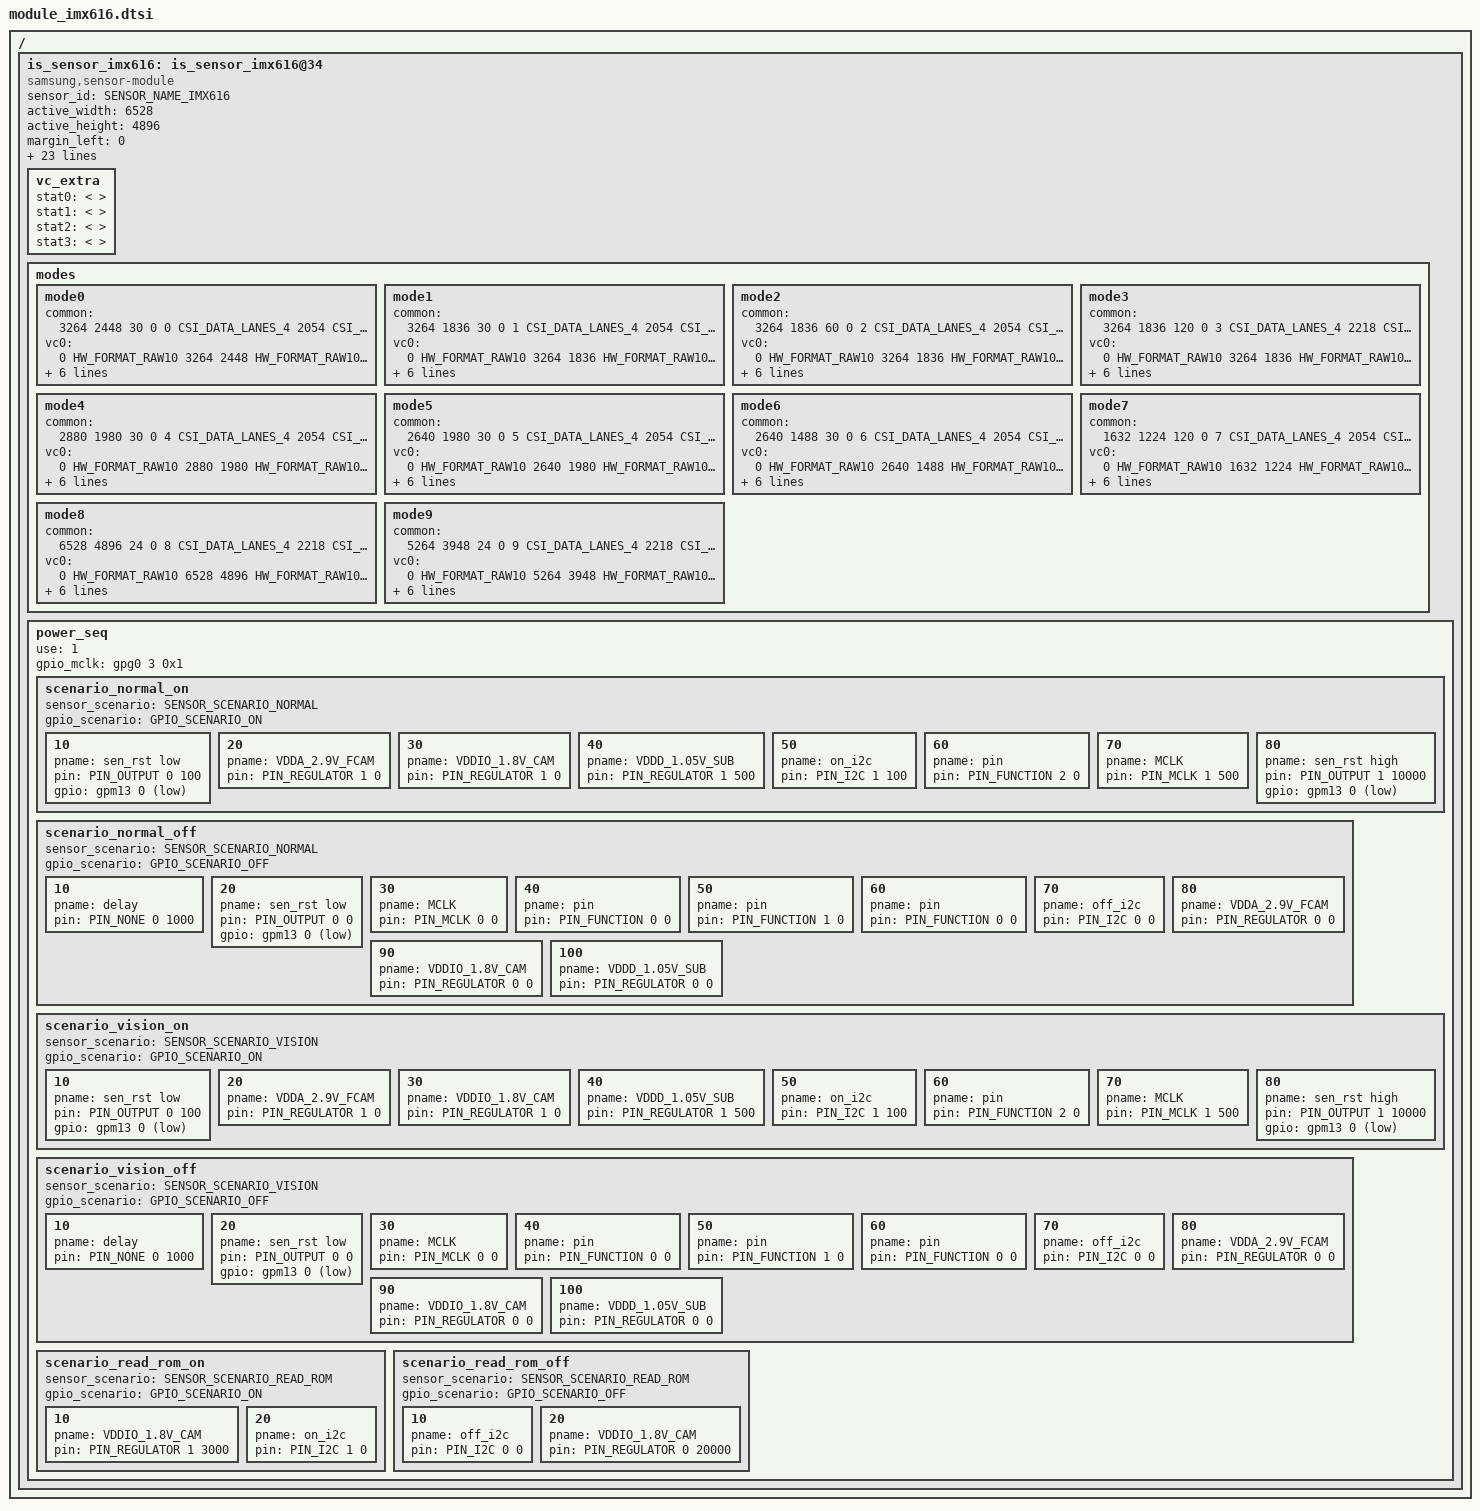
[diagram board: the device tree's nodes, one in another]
/*
 * SAMSUNG EXYNOSxxxx board camera device tree source
 *
 * Copyright (c) 2021 Samsung Electronics Co., Ltd.
 *		http://www.samsung.com
 *
 * This program is free software; you can redistribute it and/or modify
 * it under the terms of the GNU General Public License version 2 as
 * published by the Free Software Foundation.
 */

#include <dt-bindings/camera/exynos_is_dt.h>

#ifndef USE_VENDOR_PWR_PIN_NAME
#define IMX616_IOVDD	<>     /* CAM_VDDIO_1P8 : CAM0_VLDO3 is used for all camera commonly */
#define IMX616_AVDD	<>     /* RCAM1_AVDD1_2P9 */
#define IMX616_DVDD	<>     /* RCAM1_DVDD_1P1 */
#endif

/ {
	fragment@camera {
		target-path = "/";
		__overlay__ {
			is_sensor_imx616: is_sensor_imx616@34 {
				compatible = "samsung,sensor-module";

				/* common */
				sensor_id = <SENSOR_NAME_IMX616>;
				active_width = <6528>;
				active_height = <4896>;
				margin_left = <0>;
				margin_right = <0>;
				margin_top = <0>;
				margin_bottom = <0>;
				max_framerate = <120>;
				bitwidth = <10>;
				use_retention_mode = <SENSOR_RETENTION_INACTIVE>;
				sensor_maker = "SONY";
				sensor_name = "IMX616";
				setfile_name = "setfile_imx616.bin";

				imx616_iovdd-supply = IMX616_IOVDD;
				imx616_avdd-supply = IMX616_AVDD;
				imx616_dvdd-supply = IMX616_DVDD;

				status = "okay";

				/* board */
				pinctrl-names = "pin0", "pin1", "pin2", "release";
				pinctrl-0 = <>;
				pinctrl-1 = <&sensor_mclk1_out>;
				pinctrl-2 = <&sensor_mclk1_fn>;
				pinctrl-3 = <>;

				position = <1>;	/* Rear:0. Front:1. Rear_sub:2. Secure:3. */
				id = <1>; /* is_sensor id */
				mclk_ch = <1>;
				sensor_i2c_ch = <5>; /* SENSOR_CONTROL_I2C4 */

				/* vendor */
				rom_type = <2>; /* ROM_TYPE_EEPROM */
				rom_id = <1>;
				rom_cal_index = <0>;

				vc_extra {
					/* ex) statX = <stat_type, sensor_mode, max_width, max_height, max_element> */
					/* VC_BUF_DATA_TYPE_SENSOR_STAT1 */
					stat0 = </* not available */>;
					/* VC_BUF_DATA_TYPE_GENERAL_STAT1 */
					stat1 = </* not available */>;
					/* VC_BUF_DATA_TYPE_SENSOR_STAT2 */
					stat2 = </* not available */>;
					/* VC_BUF_DATA_TYPE_GENERAL_STAT2 */
					stat3 = </* not available */>;
				};

				/*
				 * Reference File : IMX616-AAJH5_SAM-DPHY_26MHz_RegisterSetting_ver14.00-20.01_b1_191023.xlsx
				 *
				 * -. 2x2 BIN For Single Still Preview / Capture / Video -
				 *    [ 0 ] REG_H : 2x2 Binning 3264x2448 30fps    : Single Still Preview (4:3)     ,  MIPI lane: 4, MIPI data rate(Mbps/lane): 2054
				 *    [ 1 ] REG_I : 2x2 Binning 3264x1836 30fps    : Single Still Preview (16:9)    ,  MIPI lane: 4, MIPI data rate(Mbps/lane): 2054
				 *    [ 2 ] REG_T : 2x2 Binning 3264x1836 60fps    : Single Video (16:9)            ,  MIPI lane: 4, MIPI data rate(Mbps/lane): 2054
				 *    [ 3 ] REG_I_2 : 2x2 Binning 3264x1836 120fps : Single Video (16:9)            ,  MIPI lane: 4, MIPI data rate(Mbps/lane): 2054
				 * -. 68 deg 2x2 BIN For Single Still Preview / Capture -
				 *    [ 4 ] REG_AB : 2x2 Binning 2880x1980 30fps   : Single Still Preview (16:9)  ,  MIPI lane: 4, MIPI data rate(Mbps/lane): 2054
				 *    [ 5 ] REG_K : 2x2 Binning 2640x1980 30fps    : Single Still Preview (4:3)     ,  MIPI lane: 4, MIPI data rate(Mbps/lane): 2054
				 *    [ 6 ] REG_L : 2x2 Binning 2640x1488 30fps    : Single Still Preview (16:9)    ,  MIPI lane: 4, MIPI data rate(Mbps/lane): 2054
				 * -. 2x2 BIN H2V2 For FastAE
				 *    [ 7 ] REG_R_2 : 2x2 Binning 1632x1224 120fps   : FAST AE (4:3)               ,  MIPI lane: 4, MIPI data rate(Mbps/lane): 2054
				 * -. FULL Remosaic For Single Still Remosaic Capture -
				 *    [ 8 ] REG_F  : Full Remosaic 6528x4896 24fps   : Single Still Remosaic Capture (4:3) , MIPI lane: 4, MIPI data rate(Mbps/lane): 2218
				 *
				 * -. 68 deg FULL Remosaic For Single Still Remosaic Capture -
				 *    [ 9 ] REG_G : Full Remosaic 5264x3948 24fps    : Single Still Remosaic Capture (4:3) , MIPI lane: 4, MIPI data rate(Mbps/lane): 2218
				 *
				 */

				/* sensor modes */
				modes {
						/* common = <width, height, fps, settle, mode, lane, speed, interleave, lrte, pd_mode> */
						/* vcX = <map, hwformat, width, height, hwformat, type, width, height> */

					/* 0 : 2X2BIN_3264x2448_30FPS */
					mode0 {
						common = <3264 2448 30 0 0 CSI_DATA_LANES_4 2054 CSI_MODE_DT_ONLY LRTE_DISABLE PD_NONE EX_NONE>;
						vc0 = </* in */ 0 HW_FORMAT_RAW10 3264 2448	/* out */ HW_FORMAT_RAW10 VC_NOTHING 0 0>;
						vc1 = </* in */ 1 HW_FORMAT_UNKNOWN 0 0		/* out */ HW_FORMAT_UNKNOWN VC_NOTHING 0 0>;
						vc2 = </* in */ 2 HW_FORMAT_UNKNOWN 0 0		/* out */ HW_FORMAT_UNKNOWN VC_NOTHING 0 0>;
						vc3 = </* in */ 3 HW_FORMAT_UNKNOWN 0 0		/* out */ HW_FORMAT_UNKNOWN VC_NOTHING 0 0>;
					};
					/* 1 : 2X2BIN_3264x1836_30FPS */
					mode1 {
						common = <3264 1836 30 0 1 CSI_DATA_LANES_4 2054 CSI_MODE_DT_ONLY LRTE_DISABLE PD_NONE EX_NONE>;
						vc0 = </* in */ 0 HW_FORMAT_RAW10 3264 1836	/* out */ HW_FORMAT_RAW10 VC_NOTHING 0 0>;
						vc1 = </* in */ 1 HW_FORMAT_UNKNOWN 0 0		/* out */ HW_FORMAT_UNKNOWN VC_NOTHING 0 0>;
						vc2 = </* in */ 2 HW_FORMAT_UNKNOWN 0 0		/* out */ HW_FORMAT_UNKNOWN VC_NOTHING 0 0>;
						vc3 = </* in */ 3 HW_FORMAT_UNKNOWN 0 0		/* out */ HW_FORMAT_UNKNOWN VC_NOTHING 0 0>;
					};
					/* 2 : 2X2BIN_3264x1836_60FPS */
					mode2 {
						common = <3264 1836 60 0 2 CSI_DATA_LANES_4 2054 CSI_MODE_DT_ONLY LRTE_DISABLE PD_NONE EX_NONE>;
						vc0 = </* in */ 0 HW_FORMAT_RAW10 3264 1836	/* out */ HW_FORMAT_RAW10 VC_NOTHING 0 0>;
						vc1 = </* in */ 1 HW_FORMAT_UNKNOWN 0 0		/* out */ HW_FORMAT_UNKNOWN VC_NOTHING 0 0>;
						vc2 = </* in */ 2 HW_FORMAT_UNKNOWN 0 0		/* out */ HW_FORMAT_UNKNOWN VC_NOTHING 0 0>;
						vc3 = </* in */ 3 HW_FORMAT_UNKNOWN 0 0		/* out */ HW_FORMAT_UNKNOWN VC_NOTHING 0 0>;
					};
					/* 3 : 2X2BIN_3264x1836_120FPS */
					mode3 {
						common = <3264 1836 120 0 3 CSI_DATA_LANES_4 2218 CSI_MODE_DT_ONLY LRTE_DISABLE PD_NONE EX_NONE>;
						vc0 = </* in */ 0 HW_FORMAT_RAW10 3264 1836	/* out */ HW_FORMAT_RAW10 VC_NOTHING 0 0>;
						vc1 = </* in */ 1 HW_FORMAT_UNKNOWN 0 0		/* out */ HW_FORMAT_UNKNOWN VC_NOTHING 0 0>;
						vc2 = </* in */ 2 HW_FORMAT_UNKNOWN 0 0		/* out */ HW_FORMAT_UNKNOWN VC_NOTHING 0 0>;
						vc3 = </* in */ 3 HW_FORMAT_UNKNOWN 0 0		/* out */ HW_FORMAT_UNKNOWN VC_NOTHING 0 0>;
					};
					/* 4 : 68Crop 2X2BIN_2880x1980_30FPS */
					mode4 {
						common = <2880 1980 30 0 4 CSI_DATA_LANES_4 2054 CSI_MODE_DT_ONLY LRTE_DISABLE PD_NONE EX_NONE>;
						vc0 = </* in */ 0 HW_FORMAT_RAW10 2880 1980	/* out */ HW_FORMAT_RAW10 VC_NOTHING 0 0>;
						vc1 = </* in */ 1 HW_FORMAT_UNKNOWN 0 0		/* out */ HW_FORMAT_UNKNOWN VC_NOTHING 0 0>;
						vc2 = </* in */ 2 HW_FORMAT_UNKNOWN 0 0		/* out */ HW_FORMAT_UNKNOWN VC_NOTHING 0 0>;
						vc3 = </* in */ 3 HW_FORMAT_UNKNOWN 0 0		/* out */ HW_FORMAT_UNKNOWN VC_NOTHING 0 0>;
					};
					/* 5 : 68Crop 2X2BIN_2640x1980_30FPS */
					mode5 {
						common = <2640 1980 30 0 5 CSI_DATA_LANES_4 2054 CSI_MODE_DT_ONLY LRTE_DISABLE PD_NONE EX_NONE>;
						vc0 = </* in */ 0 HW_FORMAT_RAW10 2640 1980	/* out */ HW_FORMAT_RAW10 VC_NOTHING 0 0>;
						vc1 = </* in */ 1 HW_FORMAT_UNKNOWN 0 0		/* out */ HW_FORMAT_UNKNOWN VC_NOTHING 0 0>;
						vc2 = </* in */ 2 HW_FORMAT_UNKNOWN 0 0		/* out */ HW_FORMAT_UNKNOWN VC_NOTHING 0 0>;
						vc3 = </* in */ 3 HW_FORMAT_UNKNOWN 0 0		/* out */ HW_FORMAT_UNKNOWN VC_NOTHING 0 0>;
					};
					/* 6 : 68Crop 2X2BIN_2640x1488_30FPS */
					mode6 {
						common = <2640 1488 30 0 6 CSI_DATA_LANES_4 2054 CSI_MODE_DT_ONLY LRTE_DISABLE PD_NONE EX_NONE>;
						vc0 = </* in */ 0 HW_FORMAT_RAW10 2640 1488	/* out */ HW_FORMAT_RAW10 VC_NOTHING 0 0>;
						vc1 = </* in */ 1 HW_FORMAT_UNKNOWN 0 0		/* out */ HW_FORMAT_UNKNOWN VC_NOTHING 0 0>;
						vc2 = </* in */ 2 HW_FORMAT_UNKNOWN 0 0		/* out */ HW_FORMAT_UNKNOWN VC_NOTHING 0 0>;
						vc3 = </* in */ 3 HW_FORMAT_UNKNOWN 0 0		/* out */ HW_FORMAT_UNKNOWN VC_NOTHING 0 0>;
					};
					/* 7 : H2V2_1632x1224_120FPS */
					mode7 {
						common = <1632 1224 120 0 7 CSI_DATA_LANES_4 2054 CSI_MODE_DT_ONLY LRTE_DISABLE PD_NONE EX_NONE>;
						vc0 = </* in */ 0 HW_FORMAT_RAW10 1632 1224	/* out */ HW_FORMAT_RAW10 VC_NOTHING 0 0>;
						vc1 = </* in */ 1 HW_FORMAT_UNKNOWN 0 0		/* out */ HW_FORMAT_UNKNOWN VC_NOTHING 0 0>;
						vc2 = </* in */ 2 HW_FORMAT_UNKNOWN 0 0		/* out */ HW_FORMAT_UNKNOWN VC_NOTHING 0 0>;
						vc3 = </* in */ 3 HW_FORMAT_UNKNOWN 0 0		/* out */ HW_FORMAT_UNKNOWN VC_NOTHING 0 0>;
					};
					/* 8 : REMOSAIC_6528x4896_24FPS */
					mode8 {
						common = <6528 4896 24 0 8 CSI_DATA_LANES_4 2218 CSI_MODE_DT_ONLY LRTE_DISABLE PD_NONE EX_NONE>;
						vc0 = </* in */ 0 HW_FORMAT_RAW10 6528 4896	/* out */ HW_FORMAT_RAW10 VC_NOTHING 0 0>;
						vc1 = </* in */ 1 HW_FORMAT_UNKNOWN 0 0		/* out */ HW_FORMAT_UNKNOWN VC_NOTHING 0 0>;
						vc2 = </* in */ 2 HW_FORMAT_UNKNOWN 0 0		/* out */ HW_FORMAT_UNKNOWN VC_NOTHING 0 0>;
						vc3 = </* in */ 3 HW_FORMAT_UNKNOWN 0 0		/* out */ HW_FORMAT_UNKNOWN VC_NOTHING 0 0>;
					};
					/* 9 : 68Crop REMOSAIC_5264x3948_24FPS */
					mode9 {
						common = <5264 3948 24 0 9 CSI_DATA_LANES_4 2218 CSI_MODE_DT_ONLY LRTE_DISABLE PD_NONE EX_NONE>;
						vc0 = </* in */ 0 HW_FORMAT_RAW10 5264 3948	/* out */ HW_FORMAT_RAW10 VC_NOTHING 0 0>;
						vc1 = </* in */ 1 HW_FORMAT_UNKNOWN 0 0		/* out */ HW_FORMAT_UNKNOWN VC_NOTHING 0 0>;
						vc2 = </* in */ 2 HW_FORMAT_UNKNOWN 0 0		/* out */ HW_FORMAT_UNKNOWN VC_NOTHING 0 0>;
						vc3 = </* in */ 3 HW_FORMAT_UNKNOWN 0 0		/* out */ HW_FORMAT_UNKNOWN VC_NOTHING 0 0>;
					};
				};

				power_seq {
					use = <1>;
					gpio_mclk = <&gpg0 3 0x1>;

					scenario_normal_on {
						sensor_scenario = <SENSOR_SCENARIO_NORMAL>;
						gpio_scenario = <GPIO_SCENARIO_ON>;

						/* A start node number should be over the 10 for reserved number 0~9. */
						/* pname = "name"; pin = <act value delay voltage>; gpio = <gpx# # 0x1>; */
						10 { pname = "sen_rst low"; pin = <PIN_OUTPUT 0 100>; gpio = <&gpm13 0 0x1>; };
						20 { pname = "VDDA_2.9V_FCAM"; pin = <PIN_REGULATOR 1 0>; };
						30 { pname = "VDDIO_1.8V_CAM"; pin = <PIN_REGULATOR 1 0>; };
						40 { pname = "VDDD_1.05V_SUB"; pin = <PIN_REGULATOR 1 500>; };
						50 { pname = "on_i2c"; pin = <PIN_I2C 1 100>; };
						60 { pname = "pin"; pin = <PIN_FUNCTION 2 0>; };
						70 { pname = "MCLK"; pin = <PIN_MCLK 1 500>; };
						80 { pname = "sen_rst high"; pin = <PIN_OUTPUT 1 10000>; gpio = <&gpm13 0 0x1>; };
					};

					scenario_normal_off {
						sensor_scenario = <SENSOR_SCENARIO_NORMAL>;
						gpio_scenario = <GPIO_SCENARIO_OFF>;

						/* A start node number should be over the 10 for reserved number 0~9. */
						/* pname = "name"; pin = <act value delay voltage>; gpio = <gpx# # 0x1>; */
						10 { pname = "delay"; pin = <PIN_NONE 0 1000>; };
						20 { pname = "sen_rst low"; pin = <PIN_OUTPUT 0 0>; gpio = <&gpm13 0 0x1>; };
						30 { pname = "MCLK"; pin = <PIN_MCLK 0 0>; };
						40 { pname = "pin"; pin = <PIN_FUNCTION 0 0>; };
						50 { pname = "pin"; pin = <PIN_FUNCTION 1 0>; };
						60 { pname = "pin"; pin = <PIN_FUNCTION 0 0>; };
						70 { pname = "off_i2c"; pin = <PIN_I2C 0 0>; };
						80 { pname = "VDDA_2.9V_FCAM"; pin = <PIN_REGULATOR 0 0>; };
						90 { pname = "VDDIO_1.8V_CAM"; pin = <PIN_REGULATOR 0 0>; };
						100 { pname = "VDDD_1.05V_SUB"; pin = <PIN_REGULATOR 0 0>; };
					};

					scenario_vision_on {
						sensor_scenario = <SENSOR_SCENARIO_VISION>;
						gpio_scenario = <GPIO_SCENARIO_ON>;

						/* A start node number should be over the 10 for reserved number 0~9. */
						/* pname = "name"; pin = <act value delay voltage>; gpio = <gpx# # 0x1>; */
						10 { pname = "sen_rst low"; pin = <PIN_OUTPUT 0 100>; gpio = <&gpm13 0 0x1>; };
						20 { pname = "VDDA_2.9V_FCAM"; pin = <PIN_REGULATOR 1 0>; };
						30 { pname = "VDDIO_1.8V_CAM"; pin = <PIN_REGULATOR 1 0>; };
						40 { pname = "VDDD_1.05V_SUB"; pin = <PIN_REGULATOR 1 500>; };
						50 { pname = "on_i2c"; pin = <PIN_I2C 1 100>; };
						60 { pname = "pin"; pin = <PIN_FUNCTION 2 0>; };
						70 { pname = "MCLK"; pin = <PIN_MCLK 1 500>; };
						80 { pname = "sen_rst high"; pin = <PIN_OUTPUT 1 10000>; gpio = <&gpm13 0 0x1>; };
					};

					scenario_vision_off {
						sensor_scenario = <SENSOR_SCENARIO_VISION>;
						gpio_scenario = <GPIO_SCENARIO_OFF>;

						/* A start node number should be over the 10 for reserved number 0~9. */
						/* pname = "name"; pin = <act value delay voltage>; gpio = <gpx# # 0x1>; */
						10 { pname = "delay"; pin = <PIN_NONE 0 1000>; };
						20 { pname = "sen_rst low"; pin = <PIN_OUTPUT 0 0>; gpio = <&gpm13 0 0x1>; };
						30 { pname = "MCLK"; pin = <PIN_MCLK 0 0>; };
						40 { pname = "pin"; pin = <PIN_FUNCTION 0 0>; };
						50 { pname = "pin"; pin = <PIN_FUNCTION 1 0>; };
						60 { pname = "pin"; pin = <PIN_FUNCTION 0 0>; };
						70 { pname = "off_i2c"; pin = <PIN_I2C 0 0>; };
						80 { pname = "VDDA_2.9V_FCAM"; pin = <PIN_REGULATOR 0 0>; };
						90 { pname = "VDDIO_1.8V_CAM"; pin = <PIN_REGULATOR 0 0>; };
						100 { pname = "VDDD_1.05V_SUB"; pin = <PIN_REGULATOR 0 0>; };
					};

					scenario_read_rom_on {
						sensor_scenario = <SENSOR_SCENARIO_READ_ROM>;
						gpio_scenario = <GPIO_SCENARIO_ON>;

						/* A start node number should be over the 10 for reserved number 0~9. */
						/* pname = "name"; pin = <act value delay voltage>; gpio = <gpx# # 0x1>; */
						10 { pname = "VDDIO_1.8V_CAM"; pin = <PIN_REGULATOR 1 3000>; };
						20 { pname = "on_i2c"; pin = <PIN_I2C 1 0>; };
					};

					scenario_read_rom_off {
						sensor_scenario = <SENSOR_SCENARIO_READ_ROM>;
						gpio_scenario = <GPIO_SCENARIO_OFF>;

						/* A start node number should be over the 10 for reserved number 0~9. */
						/* pname = "name"; pin = <act value delay voltage>; gpio = <gpx# # 0x1>; */
						10 { pname = "off_i2c"; pin = <PIN_I2C 0 0>; };
						20 { pname = "VDDIO_1.8V_CAM"; pin = <PIN_REGULATOR 0 20000>; };
					};
				};
			};
		}; /* end of __overlay__ */
	}; /* end of fragment */
}; /* end of root */
